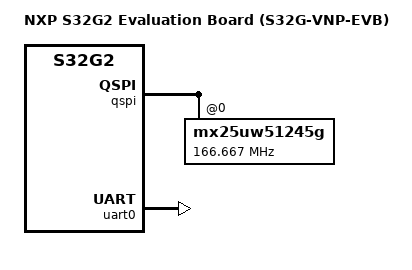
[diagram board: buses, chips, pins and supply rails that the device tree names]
// SPDX-License-Identifier: GPL-2.0-or-later OR MIT
/*
 * Copyright (c) 2021 SUSE LLC
 * Copyright 2019-2021 NXP
 */

/dts-v1/;

#include "s32g2.dtsi"
#include "s32gxxxa-evb.dtsi"

/ {
	model = "NXP S32G2 Evaluation Board (S32G-VNP-EVB)";
	compatible = "nxp,s32g274a-evb", "nxp,s32g2";
};

&qspi {
	mx25uw51245g@0 {
		spi-max-frequency = <166666666>;
	};
};

/* UART (J58) to Micro USB port */
&uart0 {
	status = "okay";
};
